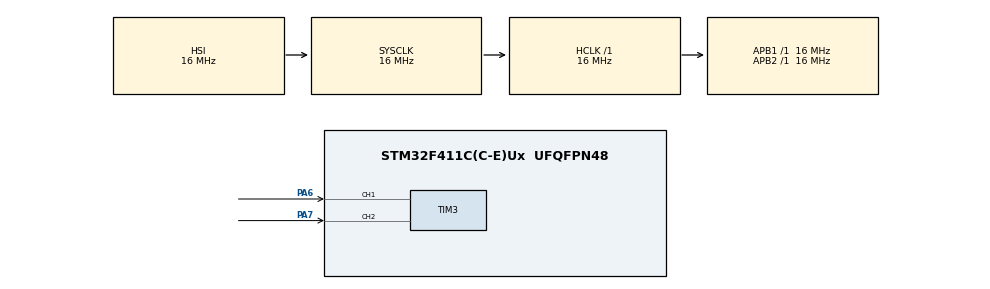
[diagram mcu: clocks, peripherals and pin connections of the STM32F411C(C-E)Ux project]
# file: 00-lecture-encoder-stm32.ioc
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Mcu.Family=STM32F4
Mcu.Name=STM32F411C(C-E)Ux
Mcu.Package=UFQFPN48
NVIC.PriorityGroup=NVIC_PRIORITYGROUP_4
PA13.Mode=Serial_Wire
PA13.Signal=SYS_JTMS-SWDIO
PA14.Mode=Serial_Wire
PA14.Signal=SYS_JTCK-SWCLK
PA6.Signal=S_TIM3_CH1
PA7.Signal=S_TIM3_CH2
ProjectManager.HeapSize=0x200
ProjectManager.StackSize=0x400
ProjectManager.TargetToolchain=STM32CubeIDE
RCC.AHBFreq_Value=16000000
RCC.APB1Freq_Value=16000000
RCC.APB2Freq_Value=16000000
RCC.CortexFreq_Value=16000000
RCC.HSE_VALUE=25000000
RCC.HSI_VALUE=16000000
RCC.LSE_VALUE=32768
RCC.SYSCLKFreq_VALUE=16000000
RCC.VCOOutputFreq_Value=192000000
SH.S_TIM3_CH1.0=TIM3_CH1,Encoder_Interface
SH.S_TIM3_CH2.0=TIM3_CH2,Encoder_Interface
TIM3.EncoderMode=TIM_ENCODERMODE_TI12
board=custom

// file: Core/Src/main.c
/* USER CODE BEGIN Header */
/**
  ******************************************************************************
  * @file           : main.c
  * @brief          : Main program body
  ******************************************************************************
  * @attention
  *
  * Copyright (c) 2026 STMicroelectronics.
  * All rights reserved.
  *
  * This software is licensed under terms that can be found in the LICENSE file
  * in the root directory of this software component.
  * If no LICENSE file comes with this software, it is provided AS-IS.
  *
  ******************************************************************************
  */
/* USER CODE END Header */
#include "main.h"

/* USER CODE BEGIN Includes */
#include "encoder.h"
/* USER CODE END Includes */

TIM_HandleTypeDef htim3;

/* USER CODE BEGIN PV */
/* Add "encoder" to Live Expressions and expand its members. */
volatile EncoderState encoder;
/* USER CODE END PV */

void SystemClock_Config(void);
static void MX_GPIO_Init(void);
static void MX_TIM3_Init(void);

int main(void)
{

  /* MCU Configuration--------------------------------------------------------*/

  /* Reset of all peripherals, Initializes the Flash interface and the Systick. */
  HAL_Init();

  /* Configure the system clock */
  SystemClock_Config();

  /* Initialize all configured peripherals */
  MX_GPIO_Init();
  MX_TIM3_Init();
  /* USER CODE BEGIN 2 */
  __HAL_TIM_SET_COUNTER(&htim3, 0U);
  Encoder_Init(&encoder, 0U, HAL_GetTick());
  if (HAL_TIM_Encoder_Start(&htim3, TIM_CHANNEL_ALL) != HAL_OK)
  {
    Error_Handler();
  }
  /* USER CODE END 2 */

  /* Infinite loop */
  while (1)
  {

    /* USER CODE BEGIN 3 */
	volatile uint16_t cnt = (uint16_t)__HAL_TIM_GET_COUNTER(&htim3);
    Encoder_Update(&encoder, cnt,HAL_GetTick());
  }
  /* USER CODE END 3 */
}

void SystemClock_Config(void)
{
  RCC_OscInitTypeDef RCC_OscInitStruct = {0};
  RCC_ClkInitTypeDef RCC_ClkInitStruct = {0};

  /** Configure the main internal regulator output voltage
  */
  __HAL_RCC_PWR_CLK_ENABLE();
  __HAL_PWR_VOLTAGESCALING_CONFIG(PWR_REGULATOR_VOLTAGE_SCALE1);

  /** Initializes the RCC Oscillators according to the specified parameters
  * in the RCC_OscInitTypeDef structure.
  */
  RCC_OscInitStruct.OscillatorType = RCC_OSCILLATORTYPE_HSI;
  RCC_OscInitStruct.HSIState = RCC_HSI_ON;
  RCC_OscInitStruct.HSICalibrationValue = RCC_HSICALIBRATION_DEFAULT;
  RCC_OscInitStruct.PLL.PLLState = RCC_PLL_NONE;
  if (HAL_RCC_OscConfig(&RCC_OscInitStruct) != HAL_OK)
  {
    Error_Handler();
  }

  /** Initializes the CPU, AHB and APB buses clocks
  */
  RCC_ClkInitStruct.ClockType = RCC_CLOCKTYPE_HCLK|RCC_CLOCKTYPE_SYSCLK
                              |RCC_CLOCKTYPE_PCLK1|RCC_CLOCKTYPE_PCLK2;
  RCC_ClkInitStruct.SYSCLKSource = RCC_SYSCLKSOURCE_HSI;
  RCC_ClkInitStruct.AHBCLKDivider = RCC_SYSCLK_DIV1;
  RCC_ClkInitStruct.APB1CLKDivider = RCC_HCLK_DIV1;
  RCC_ClkInitStruct.APB2CLKDivider = RCC_HCLK_DIV1;

  if (HAL_RCC_ClockConfig(&RCC_ClkInitStruct, FLASH_LATENCY_0) != HAL_OK)
  {
    Error_Handler();
  }
}

static void MX_TIM3_Init(void)
{

  TIM_Encoder_InitTypeDef sConfig = {0};
  TIM_MasterConfigTypeDef sMasterConfig = {0};

  htim3.Instance = TIM3;
  htim3.Init.Prescaler = 0;
  htim3.Init.CounterMode = TIM_COUNTERMODE_UP;
  htim3.Init.Period = 65535;
  htim3.Init.ClockDivision = TIM_CLOCKDIVISION_DIV1;
  htim3.Init.AutoReloadPreload = TIM_AUTORELOAD_PRELOAD_DISABLE;
  sConfig.EncoderMode = TIM_ENCODERMODE_TI12;
  sConfig.IC1Polarity = TIM_ICPOLARITY_RISING;
  sConfig.IC1Selection = TIM_ICSELECTION_DIRECTTI;
  sConfig.IC1Prescaler = TIM_ICPSC_DIV1;
  sConfig.IC1Filter = 0;
  sConfig.IC2Polarity = TIM_ICPOLARITY_RISING;
  sConfig.IC2Selection = TIM_ICSELECTION_DIRECTTI;
  sConfig.IC2Prescaler = TIM_ICPSC_DIV1;
  sConfig.IC2Filter = 0;
  if (HAL_TIM_Encoder_Init(&htim3, &sConfig) != HAL_OK)
  {
    Error_Handler();
  }
  sMasterConfig.MasterOutputTrigger = TIM_TRGO_RESET;
  sMasterConfig.MasterSlaveMode = TIM_MASTERSLAVEMODE_DISABLE;
  if (HAL_TIMEx_MasterConfigSynchronization(&htim3, &sMasterConfig) != HAL_OK)
  {
    Error_Handler();
  }

}

static void MX_GPIO_Init(void)
{

  /* GPIO Ports Clock Enable */
  __HAL_RCC_GPIOA_CLK_ENABLE();

}

void Error_Handler(void)
{
  __disable_irq();
  while (1)
  {
  }
}
